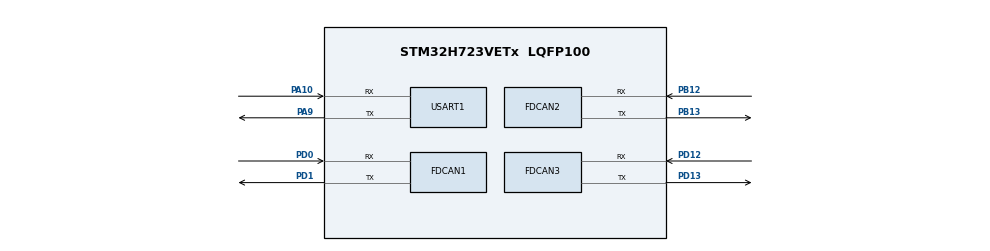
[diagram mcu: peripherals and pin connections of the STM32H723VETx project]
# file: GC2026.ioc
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Dma.Request0=USART1_RX
Dma.USART1_RX.0.Direction=DMA_PERIPH_TO_MEMORY
Dma.USART1_RX.0.EventEnable=DISABLE
Dma.USART1_RX.0.FIFOMode=DMA_FIFOMODE_DISABLE
Dma.USART1_RX.0.Instance=DMA1_Stream0
Dma.USART1_RX.0.MemDataAlignment=DMA_MDATAALIGN_BYTE
Dma.USART1_RX.0.MemInc=DMA_MINC_ENABLE
Dma.USART1_RX.0.Mode=DMA_CIRCULAR
Dma.USART1_RX.0.PeriphDataAlignment=DMA_PDATAALIGN_BYTE
Dma.USART1_RX.0.PeriphInc=DMA_PINC_DISABLE
Dma.USART1_RX.0.Polarity=HAL_DMAMUX_REQ_GEN_RISING
Dma.USART1_RX.0.Priority=DMA_PRIORITY_LOW
Dma.USART1_RX.0.RequestNumber=1
Dma.USART1_RX.0.SignalID=NONE
Dma.USART1_RX.0.SyncEnable=DISABLE
Dma.USART1_RX.0.SyncPolarity=HAL_DMAMUX_SYNC_NO_EVENT
Dma.USART1_RX.0.SyncRequestNumber=1
Dma.USART1_RX.0.SyncSignalID=NONE
FDCAN1.CalculateBaudRateNominal=1000000
FDCAN1.CalculateTimeBitNominal=1000
FDCAN1.CalculateTimeQuantumNominal=25.0
FDCAN1.DataPrescaler=3
FDCAN1.DataSyncJumpWidth=10
FDCAN1.DataTimeSeg1=29
FDCAN1.DataTimeSeg2=10
FDCAN1.NominalPrescaler=3
FDCAN1.NominalSyncJumpWidth=10
FDCAN1.NominalTimeSeg1=29
FDCAN1.NominalTimeSeg2=10
FDCAN1.RxBuffersNbr=8
FDCAN1.RxFifo0ElmtsNbr=8
FDCAN1.StdFiltersNbr=1
FDCAN1.TxFifoQueueElmtsNbr=8
FDCAN2.CalculateBaudRateNominal=1000000
FDCAN2.CalculateTimeBitNominal=1000
FDCAN2.CalculateTimeQuantumNominal=25.0
FDCAN2.DataPrescaler=3
FDCAN2.DataSyncJumpWidth=10
FDCAN2.DataTimeSeg1=29
FDCAN2.DataTimeSeg2=10
FDCAN2.NominalPrescaler=3
FDCAN2.NominalSyncJumpWidth=10
FDCAN2.NominalTimeSeg1=29
FDCAN2.NominalTimeSeg2=10
FDCAN3.CalculateBaudRateNominal=1000000
FDCAN3.CalculateTimeBitNominal=1000
FDCAN3.CalculateTimeQuantumNominal=25.0
FDCAN3.DataPrescaler=3
FDCAN3.DataSyncJumpWidth=10
FDCAN3.DataTimeSeg1=29
FDCAN3.DataTimeSeg2=10
FDCAN3.NominalPrescaler=3
FDCAN3.NominalSyncJumpWidth=10
FDCAN3.NominalTimeSeg1=29
FDCAN3.NominalTimeSeg2=10
FREERTOS.Tasks01=defaultTask,24,128,StartDefaultTask,Default,NULL,Dynamic,NULL,NULL
Mcu.Family=STM32H7
Mcu.Name=STM32H723VETx
Mcu.Package=LQFP100
NVIC.DMA1_Stream0_IRQn=true\:5\:0\:false\:false\:true\:true\:false\:true\:true
NVIC.FDCAN1_IT0_IRQn=true\:5\:0\:false\:false\:true\:true\:true\:true\:true
NVIC.PriorityGroup=NVIC_PRIORITYGROUP_4
NVIC.TIM1_UP_IRQn=true\:15\:0\:false\:false\:true\:false\:false\:true\:true
NVIC.TIM2_IRQn=true\:5\:0\:false\:false\:true\:true\:true\:true\:true
NVIC.TIM3_IRQn=true\:5\:0\:false\:false\:true\:true\:true\:true\:true
NVIC.TimeBase=TIM1_UP_IRQn
NVIC.TimeBaseIP=TIM1
NVIC.USART1_IRQn=true\:5\:0\:false\:false\:true\:true\:true\:true\:true
PA10.Mode=Asynchronous
PA10.Signal=USART1_RX
PA9.Mode=Asynchronous
PA9.Signal=USART1_TX
PB12.Mode=FDCAN_Activate
PB12.Signal=FDCAN2_RX
PB13.Mode=FDCAN_Activate
PB13.Signal=FDCAN2_TX
PD0.Mode=FDCAN_Activate
PD0.Signal=FDCAN1_RX
PD1.Mode=FDCAN_Activate
PD1.Signal=FDCAN1_TX
PD12.Mode=FDCAN_Activate
PD12.Signal=FDCAN3_RX
PD13.Mode=FDCAN_Activate
PD13.Signal=FDCAN3_TX
PH0-OSC_IN.Mode=HSE-External-Oscillator
PH0-OSC_IN.Signal=RCC_OSC_IN
PH1-OSC_OUT.Mode=HSE-External-Oscillator
PH1-OSC_OUT.Signal=RCC_OSC_OUT
ProjectManager.HeapSize=0x200
ProjectManager.StackSize=0x400
ProjectManager.TargetToolchain=MDK-ARM V5.32
RCC.ADCFreq_Value=129000000
RCC.APB1Freq_Value=120000000
RCC.APB2Freq_Value=120000000
RCC.APB3Freq_Value=120000000
RCC.APB4Freq_Value=120000000
RCC.CortexFreq_Value=480000000
RCC.D1PPRE=RCC_APB3_DIV2
RCC.D2PPRE1=RCC_APB1_DIV2
RCC.D2PPRE2=RCC_APB2_DIV2
RCC.D3PPRE=RCC_APB4_DIV2
RCC.DIVM1=4
RCC.DIVN1=30
RCC.DIVP1=1
RCC.DIVQ1=4
RCC.HCLKFreq_Value=240000000
RCC.HPRE=RCC_HCLK_DIV2
RCC.HSE_VALUE=24000000
RCC.PLL2FRACN=0
RCC.PLL3FRACN=0
RCC.PLLFRACN=0
RCC.SYSCLKFreq_VALUE=480000000
RCC.SYSCLKSource=RCC_SYSCLKSOURCE_PLLCLK
RCC.USBFreq_Value=120000000
TIM2.Period=9999
TIM2.Prescaler=47999
TIM3.Period=9999
TIM3.Prescaler=47999
USART1.VirtualMode-Asynchronous=VM_ASYNC
VP_FREERTOS_VS_CMSIS_V2.Mode=CMSIS_V2
VP_MEMORYMAP_VS_MEMORYMAP.Mode=CurAppReg
VP_SYS_VS_tim1.Mode=TIM1
VP_TIM2_VS_ClockSourceINT.Mode=Internal
VP_TIM3_VS_ClockSourceINT.Mode=Internal
board=custom

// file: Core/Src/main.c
/* USER CODE BEGIN Header */
/**
  ******************************************************************************
  * @file           : main.c
  * @brief          : Main program body
  ******************************************************************************
  * @attention
  *
  * Copyright (c) 2026 STMicroelectronics.
  * All rights reserved.
  *
  * This software is licensed under terms that can be found in the LICENSE file
  * in the root directory of this software component.
  * If no LICENSE file comes with this software, it is provided AS-IS.
  *
  ******************************************************************************
  */
/* USER CODE END Header */
#include "main.h"
#include "FreeRTOS.h"
#include "cmsis_os2.h"
#include "dma.h"
#include "fdcan.h"
#include "tim.h"
#include "usart.h"
#include "gpio.h"

/* USER CODE BEGIN Includes */
#include "comm_manager.h"
/* USER CODE END Includes */

void SystemClock_Config(void);
void MX_FREERTOS_Init(void);

int main(void)
{

  /* MCU Configuration--------------------------------------------------------*/

  /* Reset of all peripherals, Initializes the Flash interface and the Systick. */
  HAL_Init();

  /* Configure the system clock */
  SystemClock_Config();

  /* Initialize all configured peripherals */
  MX_GPIO_Init();
  MX_DMA_Init();
  MX_FDCAN1_Init();
  MX_FDCAN2_Init();
  MX_FDCAN3_Init();
  MX_USART1_UART_Init();
  MX_TIM2_Init();
  MX_TIM3_Init();
  /* USER CODE BEGIN 2 */

  /* 初始化通讯管理器 (DMA+IDLE 接收, 环形缓冲, 协议解析器) */
  Comm_Init();
  HAL_FDCAN_Start(&hfdcan1);
  /* USER CODE END 2 */

  /* Init scheduler */
  osKernelInitialize();  /* Call init function for freertos objects (in cmsis_os2.c) */
  MX_FREERTOS_Init();

  /* Start scheduler */
  osKernelStart();

  /* We should never get here as control is now taken by the scheduler */

  /* Infinite loop */
  while (1)
  {

  }
}

void SystemClock_Config(void)
{
  RCC_OscInitTypeDef RCC_OscInitStruct = {0};
  RCC_ClkInitTypeDef RCC_ClkInitStruct = {0};

  /** Supply configuration update enable
  */
  HAL_PWREx_ConfigSupply(PWR_LDO_SUPPLY);

  /** Configure the main internal regulator output voltage
  */
  __HAL_PWR_VOLTAGESCALING_CONFIG(PWR_REGULATOR_VOLTAGE_SCALE0);

  while(!__HAL_PWR_GET_FLAG(PWR_FLAG_VOSRDY)) {}

  /** Initializes the RCC Oscillators according to the specified parameters
  * in the RCC_OscInitTypeDef structure.
  */
  RCC_OscInitStruct.OscillatorType = RCC_OSCILLATORTYPE_HSI;
  RCC_OscInitStruct.HSIState = RCC_HSI_DIV1;
  RCC_OscInitStruct.HSICalibrationValue = 64;
  RCC_OscInitStruct.PLL.PLLState = RCC_PLL_ON;
  RCC_OscInitStruct.PLL.PLLSource = RCC_PLLSOURCE_HSI;
  RCC_OscInitStruct.PLL.PLLM = 4;
  RCC_OscInitStruct.PLL.PLLN = 30;
  RCC_OscInitStruct.PLL.PLLP = 1;
  RCC_OscInitStruct.PLL.PLLQ = 4;
  RCC_OscInitStruct.PLL.PLLR = 2;
  RCC_OscInitStruct.PLL.PLLRGE = RCC_PLL1VCIRANGE_3;
  RCC_OscInitStruct.PLL.PLLVCOSEL = RCC_PLL1VCOWIDE;
  RCC_OscInitStruct.PLL.PLLFRACN = 0;
  if (HAL_RCC_OscConfig(&RCC_OscInitStruct) != HAL_OK)
  {
    Error_Handler();
  }

  /** Initializes the CPU, AHB and APB buses clocks
  */
  RCC_ClkInitStruct.ClockType = RCC_CLOCKTYPE_HCLK|RCC_CLOCKTYPE_SYSCLK
                              |RCC_CLOCKTYPE_PCLK1|RCC_CLOCKTYPE_PCLK2
                              |RCC_CLOCKTYPE_D3PCLK1|RCC_CLOCKTYPE_D1PCLK1;
  RCC_ClkInitStruct.SYSCLKSource = RCC_SYSCLKSOURCE_PLLCLK;
  RCC_ClkInitStruct.SYSCLKDivider = RCC_SYSCLK_DIV1;
  RCC_ClkInitStruct.AHBCLKDivider = RCC_HCLK_DIV2;
  RCC_ClkInitStruct.APB3CLKDivider = RCC_APB3_DIV2;
  RCC_ClkInitStruct.APB1CLKDivider = RCC_APB1_DIV2;
  RCC_ClkInitStruct.APB2CLKDivider = RCC_APB2_DIV2;
  RCC_ClkInitStruct.APB4CLKDivider = RCC_APB4_DIV2;

  if (HAL_RCC_ClockConfig(&RCC_ClkInitStruct, FLASH_LATENCY_3) != HAL_OK)
  {
    Error_Handler();
  }
}

// void HAL_TIM_PeriodElapsedCallback(TIM_HandleTypeDef *htim)
// {
//   /* USER CODE BEGIN Callback 0 */

//   /* USER CODE END Callback 0 */
//   if (htim->Instance == TIM1)
//   {
//     HAL_IncTick();
//   }
//   /* USER CODE BEGIN Callback 1 */

//   /* USER CODE END Callback 1 */
// }

void Error_Handler(void)
{
  __disable_irq();
  while (1)
  {
  }
}

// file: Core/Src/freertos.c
/* USER CODE BEGIN Header */
/**
  ******************************************************************************
  * File Name          : freertos.c
  * Description        : Code for freertos applications
  ******************************************************************************
  * @attention
  *
  * Copyright (c) 2026 STMicroelectronics.
  * All rights reserved.
  *
  * This software is licensed under terms that can be found in the LICENSE file
  * in the root directory of this software component.
  * If no LICENSE file comes with this software, it is provided AS-IS.
  *
  ******************************************************************************
  */
/* USER CODE END Header */

#include "FreeRTOS.h"
#include "task.h"
#include "main.h"
#include "FreeRTOS.h"
#include "cmsis_os2.h"

/* USER CODE BEGIN Includes */
#include "comm_manager.h"
#include "ChassisControl.h"
/* USER CODE END Includes */

/* Definitions for defaultTask */
osThreadId_t defaultTaskHandle;
const osThreadAttr_t defaultTask_attributes = {
  .name = "defaultTask",
  .stack_size = 128 * 4,
  .priority = (osPriority_t) osPriorityNormal,
};

void StartDefaultTask(void *argument);

void MX_FREERTOS_Init(void); /* (MISRA C 2004 rule 8.1) */

void MX_FREERTOS_Init(void) {

  /* Create the thread(s) */
  /* creation of defaultTask */
  defaultTaskHandle = osThreadNew(StartDefaultTask, NULL, &defaultTask_attributes);

  /* USER CODE BEGIN RTOS_THREADS */
  /* add threads, ... */
  Comm_InitTask();
  Chassis_InitTask();
  /* USER CODE END RTOS_THREADS */

}

void StartDefaultTask(void *argument)
{
  for(;;)
  {
    osDelay(1);
  }
}
